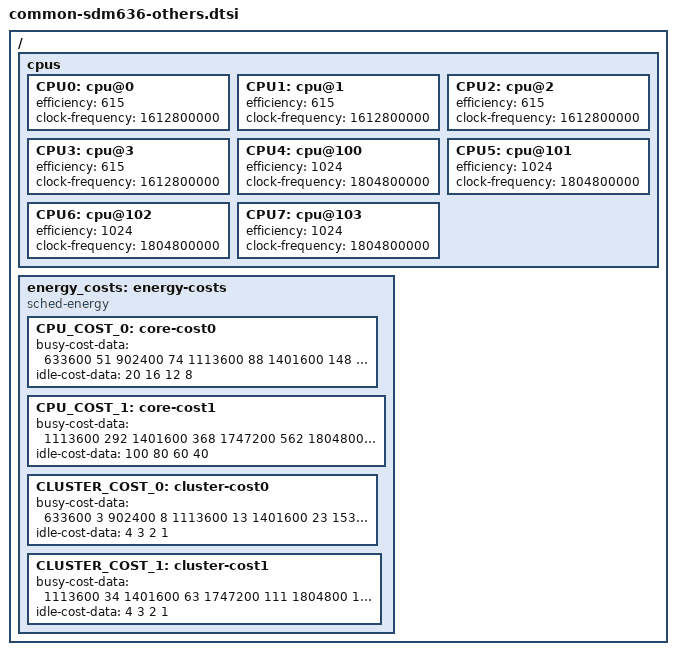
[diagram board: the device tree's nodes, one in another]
/* Copyright (c) 2016-2019, The Linux Foundation. All rights reserved.
 *
 * This program is free software; you can redistribute it and/or modify
 * it under the terms of the GNU General Public License version 2 and
 * only version 2 as published by the Free Software Foundation.
 *
 * This program is distributed in the hope that it will be useful,
 * but WITHOUT ANY WARRANTY; without even the implied warranty of
 * MERCHANTABILITY or FITNESS FOR A PARTICULAR PURPOSE.  See the
 * GNU General Public License for more details.
 */

/* sdm660.dtsi tulip/whyred specific diff */
/ {
	cpus {
		CPU0: cpu@0 {
			efficiency = <615>;
			clock-frequency = <1612800000>;
		};

		CPU1: cpu@1 {
			efficiency = <615>;
			clock-frequency = <1612800000>;
		};

		CPU2: cpu@2 {
			efficiency = <615>;
			clock-frequency = <1612800000>;
		};

		CPU3: cpu@3 {
			efficiency = <615>;
			clock-frequency = <1612800000>;
		};

		CPU4: cpu@100 {
			efficiency = <1024>;
			clock-frequency = <1804800000>;
		};

		CPU5: cpu@101 {
			efficiency = <1024>;
			clock-frequency = <1804800000>;
		};

		CPU6: cpu@102 {
			efficiency = <1024>;
			clock-frequency = <1804800000>;
		};

		CPU7: cpu@103 {
			efficiency = <1024>;
			clock-frequency = <1804800000>;
		};
	};

	energy_costs: energy-costs {
		compatible = "sched-energy";

		CPU_COST_0: core-cost0 {
			busy-cost-data = <
				 633600   51
				 902400   74
				1113600   88
				1401600  148
				1536000  162
				1612800  181
			>;
			idle-cost-data = <
				20 16 12 8
			>;
		};
		CPU_COST_1: core-cost1 {
			busy-cost-data = <
				1113600  292
				1401600  368
				1747200  562
				1804800  559
			>;
			idle-cost-data = <
				100 80 60 40
			>;
		};
		CLUSTER_COST_0: cluster-cost0 {
			busy-cost-data = <
				 633600  3
				 902400  8
				1113600 13
				1401600 23
				1536000 32
				1612800 39
			>;
			idle-cost-data = <
				4 3 2 1
			>;
		};
		CLUSTER_COST_1: cluster-cost1 {
			busy-cost-data = <
				1113600  34
				1401600  63
				1747200 111
				1804800 178
			>;
			idle-cost-data = <
				4 3 2 1
			>;
		};
	};
};
